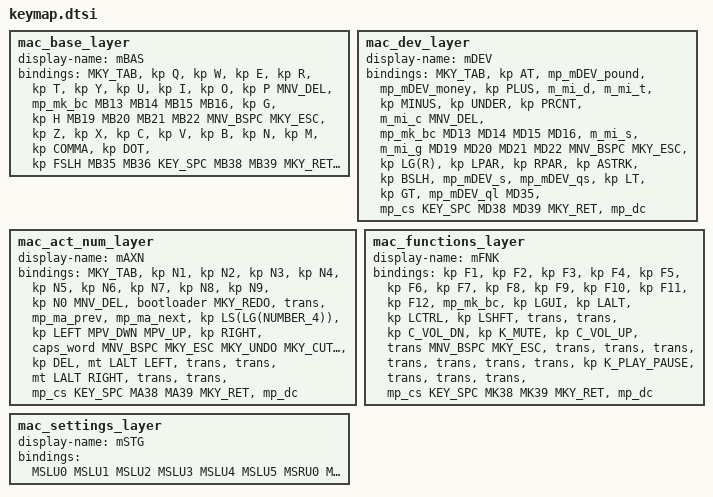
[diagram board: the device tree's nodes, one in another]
        mac_base_layer {
            #define MB13  &hm          LCMD   A
            #define MB14  &hm          LALT   S
            #define MB15  &hm          LSHFT  D
            #define MB16  &hm          LCTRL  F

            #define MB19  &hm          RCTRL  J
            #define MB20  &hm          RSHFT  K
            #define MB21  &hm          LALT   L
            #define MB22  &hm          RCMD   SEMI

            #define MB35  &mp_m_stg

            #define MB36  &mp_m_dev
            #define MB38  &mo_mAXNmBAS_to_mAXN  0  0
            #define MB39  &mo_mAXNmBAS_to_mFNK  0  0
            #define MB41  &mp_m_dev

            display-name = "mBAS";
            bindings = <
MKY_TAB       &kp Q  &kp W  &kp E    &kp R      &kp T          &kp Y    &kp U    &kp I      &kp O    &kp P      MNV_DEL
&mp_mk_bc     MB13   MB14   MB15     MB16       &kp G          &kp H    MB19     MB20       MB21     MB22       MNV_BSPC
MKY_ESC       &kp Z  &kp X  &kp C    &kp V      &kp B          &kp N    &kp M    &kp COMMA  &kp DOT  &kp FSLH   MB35
                            MB36     KEY_SPC    MB38           MB39     MKY_RET  MB41
            >;
        };

        mac_dev_layer {
            #define MD13  &hm          LCMD   AMPS
            #define MD14  &hm          LALT    LBRC
            #define MD15  &hm          LSHFT    RBRC
            #define MD16  &hm          LCTRL   EQUAL

            #define MD19  &hm_mDEV_RS  RCTRL   0
            #define MD20  &hm_mDEV_RA  RSHFT    0
            #define MD21  &hm_mDEV_RC  LALT    0
            #define MD22  &hm          RCMD   PIPE

            #define MD35  &kp LA(LG(I))                 // tap: dev tools

            #define MD38  &mo_mAXNmDEV_to_mBAS  0  0
            #define MD39  &mo_mAXNmDEV_to_mAXN  0  0

            display-name = "mDEV";
            bindings = <
    MKY_TAB     &kp AT  &mp_mDEV_pound  &mp_mDEV_money    &kp PLUS   &m_mi_d               &m_mi_t    &kp MINUS     &kp UNDER    &kp PRCNT      &m_mi_c   MNV_DEL
  &mp_mk_bc       MD13            MD14            MD15        MD16   &m_mi_s               &m_mi_g         MD19          MD20         MD21         MD22  MNV_BSPC
    MKY_ESC  &kp LG(R)        &kp LPAR        &kp RPAR   &kp ASTRK  &kp BSLH            &mp_mDEV_s  &mp_mDEV_qs        &kp LT       &kp GT  &mp_mDEV_ql      MD35
                                                &mp_cs     KEY_SPC      MD38                  MD39      MKY_RET        &mp_dc
            >;
        };

        mac_act_num_layer {
            #define MKY_UNDO   &kp RG(Z)       // tap: undo
            #define MKY_REDO   &kp RS(RG(Z))   // tap: redo
            #define MKY_CUT    &kp RG(X)       // tap: cut
            #define MKY_COPY   &kp RG(C)       // tap: copy
            #define MKY_PASTE  &mp_ma_paste    // tap: paste | shift: paste without format

            #define MA38  &to_mBAS
            #define MA39  &mo_mFNKmAXN_to_mFNK    0 0

            display-name = "mAXN";
            bindings = <
      MKY_TAB &kp N1        &kp N2      &kp N3    &kp N4        &kp N5                                  &kp N6     &kp N7     &kp N8     &kp N9      &kp N0      MNV_DEL
      &bootloader   MKY_REDO    &trans    &mp_ma_prev   &mp_ma_next  &kp LS(LG(NUMBER_4))       &kp LEFT   MPV_DWN    MPV_UP     &kp RIGHT   &caps_word  MNV_BSPC
      MKY_ESC MKY_UNDO      MKY_CUT  MKY_COPY    MKY_PASTE    &kp DEL                       &mt LALT LEFT  &trans  &trans  &mt LALT RIGHT  &trans      &trans
                             &mp_cs      KEY_SPC      MA38                   MA39  MKY_RET  &mp_dc
            >;
        };

        mac_functions_layer {
            #define MK38  &to_mBAS
            #define MK39  &to_mAXN

            display-name = "mFNK";
            bindings = <
&kp F1  &kp F2    &kp F3    &kp F4     &kp F5     &kp F6    &kp F7  &kp F8        &kp F9            &kp F10       &kp F11  &kp F12
&mp_mk_bc  &kp LGUI  &kp LALT  &kp LCTRL  &kp LSHFT  &trans    &trans  &kp C_VOL_DN  &kp K_MUTE        &kp C_VOL_UP  &trans   MNV_BSPC
MKY_ESC  &trans    &trans    &trans     &trans     &trans    &trans  &trans        &kp K_PLAY_PAUSE  &trans        &trans   &trans
                            &mp_cs  KEY_SPC   MK38                   MK39  MKY_RET     &mp_dc
            >;
        };

        mac_settings_layer {
            #define MSLU0  MKY_ESC
            #define MSLU1  &m_s_b1
            #define MSLU2  &m_s_b2
            #define MSLU3  &none
            #define MSLU4  &kp LG(LS(C))                // tap: color picker
            #define MSLU5  &kp RG(PLUS)                 // tap: zoom in

            #define MSLM0  &kp LC(LA(SPACE))            // tap: input source
            #define MSLM1  &hm_mSTG_LC  LCTRL  0        // tap: m_s_b3
            #define MSLM2  &m_s_b4
            #define MSLM3  &kp LALT
            #define MSLM4  &hm_mSTG_LS  LSHFT  0        // tap: mp_mSTG_screenshot
            #define MSLM5  &mp_ma_zoom_reset            // tap: zoom reset | shift: zoom reset on vscode

            #define MSLD0  &mp_sSTG_cb                  // tap: none | shift: clear current profile | alt: clear all profiles
            #define MSLD1  &m_s_b5
            #define MSLD2  &m_s_b6
            #define MSLD3  &none
            #define MSLD4  &mp_mSTG_f                   // tap: (finder) file explorer | alt: show/hide system files
            #define MSLD5  &kp RG(MINUS)                // tap: zoom out


            #define MSRU0  &kp C_VOL_UP
            #define MSRU1  &kp LS(LA(LG(LC(LEFT))))     // tap: rectangle top left
            #define MSRU2  &kp LS(LA(LG(UP)))           // tap: rectangle top half
            #define MSRU3  &kp LS(LA(LG(LC(RIGHT))))    // tap: rectangle top right
            #define MSRU4  &none
            #define MSRU5  &kp C_BRI_DN                        // tap: task manager

            #define MSRM0  &mp_mSTG_m                   // tap: vol mute | shift: mic mute
            #define MSRM1  &hm RSHFT  LS(LA(LG(LEFT)))  // tap: rectangle left half
            #define MSRM2  &hm_mSTG_RA  LALT 0          // tap: mp_mSTG_rectangle
            #define MSRM3  &kp LS(LA(LG(RIGHT)))        // tap: rectangle right half
            #define MSRM4  &kp LC(UP)                   // tap: mission control
            #define MSRM5  &bootloader

            #define MSRD0  &kp C_VOL_DN
            #define MSRD1  &kp LA(LG(LC(LEFT)))         // tap: rectangle bottom left
            #define MSRD2  &kp LS(LA(LG(DOWN)))         // tap: rectangle bottom half
            #define MSRD3  &kp LA(LG(LC(RIGHT)))        // tap: rectangle bottom right
            #define MSRD4  &kp LC(DOWN)                 // tap: application window
            #define MSRD5  &kp C_BRI_UP


            #define MSLT2  &none
            #define MSLT1  KEY_SPC
            #define MSLT0  &to_mBAS

            #define MSRT0  &to_mAXN
            #define MSRT1  MKY_RET
            #define MSRT2  &none


            display-name = "mSTG";
            bindings = <
              MSLU0  MSLU1  MSLU2  MSLU3  MSLU4  MSLU5    MSRU0  MSRU1  MSRU2  MSRU3  MSRU4  MSRU5
              MSLM0  MSLM1  MSLM2  MSLM3  MSLM4  MSLM5    MSRM0  MSRM1  MSRM2  MSRM3  MSRM4  MSRM5
              MSLD0  MSLD1  MSLD2  MSLD3  MSLD4  MSLD5    MSRD0  MSRD1  MSRD2  MSRD3  MSRD4  MSRD5
                                   MSLT2  MSLT1  MSLT0    MSRT0  MSRT1  MSRT2
            >;
        };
